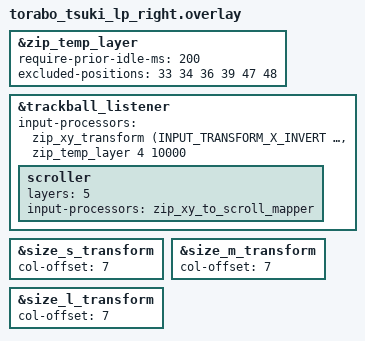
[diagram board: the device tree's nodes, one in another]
#include "torabo_tsuki_lp.dtsi"
#include <input/processors.dtsi>
#include <dt-bindings/zmk/input_transform.h>


// Require 200ms prior to idle to activate the layer
// ref: https://zenn.dev/kot149/articles/zmk-auto-mouse-layer
&zip_temp_layer {
    require-prior-idle-ms = <200>;

    excluded-positions = <
        33 // J
        34 // K
        36 // ;
        39 // Z
        47 // M
        48 // <
    >;
};

&trackball_listener {

    // Activate layer 4 then deactivate after 10 seconds
    // ref: https://zenn.dev/kot149/articles/zmk-auto-mouse-layer
    input-processors = <&zip_xy_transform (INPUT_TRANSFORM_X_INVERT | INPUT_TRANSFORM_Y_INVERT) &zip_temp_layer 4 10000>;

    // Scroll when layer 5 is active
    scroller {
        layers = <5>;
        input-processors = <&zip_xy_to_scroll_mapper>;
    }; 
};

&size_s_transform {
    col-offset = <7>;
};

&size_m_transform {
    col-offset = <7>;
};

&size_l_transform {
    col-offset = <7>;
};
